# STM32G564 register map
File version: 2.0.0
CPU: CM33 r0p4, little endian, MPU, FPU, 4 interrupt priority bits
Registers are 32-bit, read-write, reset 0x0 unless marked. A register's access mark holds for its fields unless they carry their own. Offsets are from the block's base; [hi:lo] are bit positions; {n}, {i} and the like mark numbered series.

## ICACHE — ICACHE register block
Base 0x40030400
Same registers: ICACHE_S 0x50030400
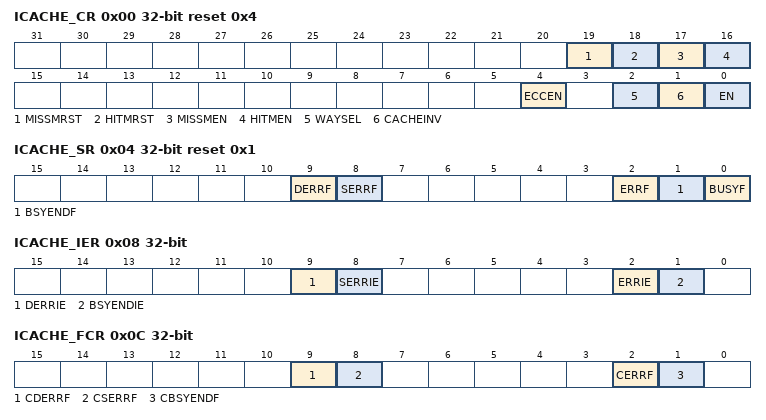
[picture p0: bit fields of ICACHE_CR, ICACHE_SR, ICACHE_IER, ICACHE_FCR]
0x00 ICACHE_CR reset 0x4 — ICACHE control register
  [19] MISSMRST — miss monitor reset
    0=release the cache miss monitor reset (needed to enable the counting); 1=reset cache miss monitor
  [18] HITMRST — hit monitor reset
    0=release the cache miss monitor reset (needed to enable the counting); 1=reset cache hit monitor
  [17] MISSMEN — miss monitor enable
    0=cache miss monitor switched off. Stopping the monitor does not reset it.; 1=cache miss monitor enabled
  [16] HITMEN — hit monitor enable
    0=cache hit monitor switched off. Stopping the monitor does not reset it.; 1=cache hit monitor enabled
  [4] ECCEN — ECC enable
    0=ECC encoder and decoder disabled; 1=ECC encoder and decoder enabled
  [2] WAYSEL — cache associativity mode selection
    0=direct mapped cache (1-way cache); 1=n-way set associative cache (reset value)
  [1] CACHEINV wo — cache invalidation
    0=no effect; 1=invalidate entire cache (all cache lines valid bit and TAG/ECC/data = 0)
  [0] EN — enable
    0=cache disabled; 1=cache enabled
0x04 ICACHE_SR reset 0x1 — ICACHE status register
  [9] DERRF — ECC double-bit error flag
    0=no ECC double-bit error detected; 1=an ECC double-bit error was detected
  [8] SERRF — ECC single-bit error flag
    0=no ECC single-bit error detected; 1=an ECC single-bit error was detected
  [2] ERRF ro — cache error flag
    0=no error; 1=an error occurred during the operation (cacheable write)
  [1] BSYENDF ro — busy end flag
    0=cache busy; 1=full invalidate CACHEINV operation finished
  [0] BUSYF ro — busy flag
    0=cache not busy on a CACHEINV operation; 1=cache executing a full invalidate CACHEINV operation
0x08 ICACHE_IER — ICACHE interrupt enable register
  [9] DERRIE — interrupt enable on ECC double-bit error detection
    0=interrupt disabled on ECC double-bit error detection; 1=interrupt enabled on ECC double-bit error detection
  [8] SERRIE — interrupt enable on ECC single-bit error detection
    0=interrupt disabled on ECC single-bit error detection; 1=interrupt enabled on ECC single-bit error detection
  [2] ERRIE — interrupt enable on cache error
    0=interrupt disabled on error; 1=interrupt enabled on error
  [1] BSYENDIE — interrupt enable on busy end
    0=interrupt disabled on busy end; 1=interrupt enabled on busy end
0x0C ICACHE_FCR wo — ICACHE flag clear register
  [9] CDERRF — clear ECC double-bit error flag
    0=no effect; 1=clears DERRF flag in ICACHE_SR
  [8] CSERRF — clear ECC single-bit error flag
    0=no effect; 1=clears SERRF flag in ICACHE_SR
  [2] CERRF — clear cache error flag
    0=no effect; 1=clears ERRF flag in ICACHE_SR
  [1] CBSYENDF — clear busy end flag
    0=no effect; 1=clears BSYENDF flag in ICACHE_SR
0x10 ICACHE_HMONR ro — ICACHE hit monitor register
  [31:0] HITMON — cache hit monitor counter
0x14 ICACHE_MMONR ro — ICACHE miss monitor register
  [15:0] MISSMON — cache miss monitor counter
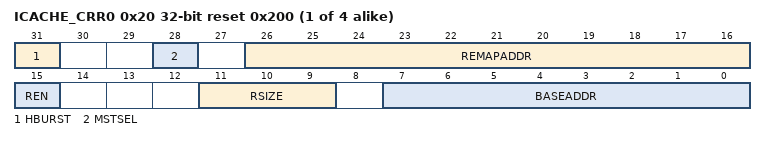
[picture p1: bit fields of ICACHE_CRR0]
{0x20+4i} ICACHE_CRR{i} reset 0x200 (i=0..3) — ICACHE region {i} configuration register
  [31] HBURST — output burst type for region x
    0=WRAP; 1=INCR
  [28] MSTSEL — AHB cache master selection for region x
    0=no action (master1 selected by default); 1=master2 selected
  [26:16] REMAPADDR — remapped address for region x
  [15] REN — enable for region x
    0=disabled; 1=enabled
  [11:9] RSIZE — size for region x
    1=2 Mbytes; 2=4 Mbytes; 3=8 Mbytes; 4=16 Mbytes; 5=32 Mbytes; 6=64 Mbytes; 7=128 Mbytes
  [7:0] BASEADDR — base address for region x

## IWDG — IWDG address block description
Base 0x40003400
Same registers: IWDG_S 0x50003400
0x00 IWDG_KR wo — IWDG key register
  [15:0] KEY — Key value (write only, read 0x0000)
0x04 IWDG_PR — IWDG prescaler register
  [3:0] PR — Prescaler divider
    0=divider / 4; 1=divider / 8; 2=divider / 16; 3=divider / 32; 4=divider / 64; 5=divider / 128; 6=divider / 256; 7=divider / 512
0x08 IWDG_RLR reset 0xFFF — IWDG reload register
  [11:0] RL — Watchdog counter reload value
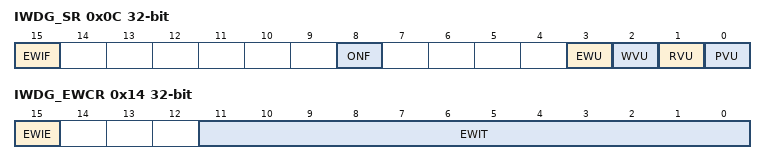
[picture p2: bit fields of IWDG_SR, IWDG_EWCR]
0x0C IWDG_SR ro — IWDG status register
  [15] EWIF — Watchdog early interrupt flag
  [8] ONF — Watchdog enable status bit
    0=The IWDG is not activated; 1=The IWDG is activated and needs to be refreshed regularly by the application
  [3] EWU — Watchdog interrupt comparator value update
  [2] WVU — Watchdog counter window value update
  [1] RVU — Watchdog counter reload value update
  [0] PVU — Watchdog prescaler value update
0x10 IWDG_WINR reset 0xFFF — IWDG window register
  [11:0] WIN — Watchdog counter window value
0x14 IWDG_EWCR — IWDG early wake-up interrupt register
  [15] EWIE — Watchdog early interrupt enable
    0=The early interrupt interface is disabled; 1=The early interrupt interface is enabled
  [11:0] EWIT — Watchdog counter early wake-up interrupt value
0x18 IWDG_ICR — IWDG interrupt clear register
  [15] EWIC — Watchdog early interrupt acknowledge
